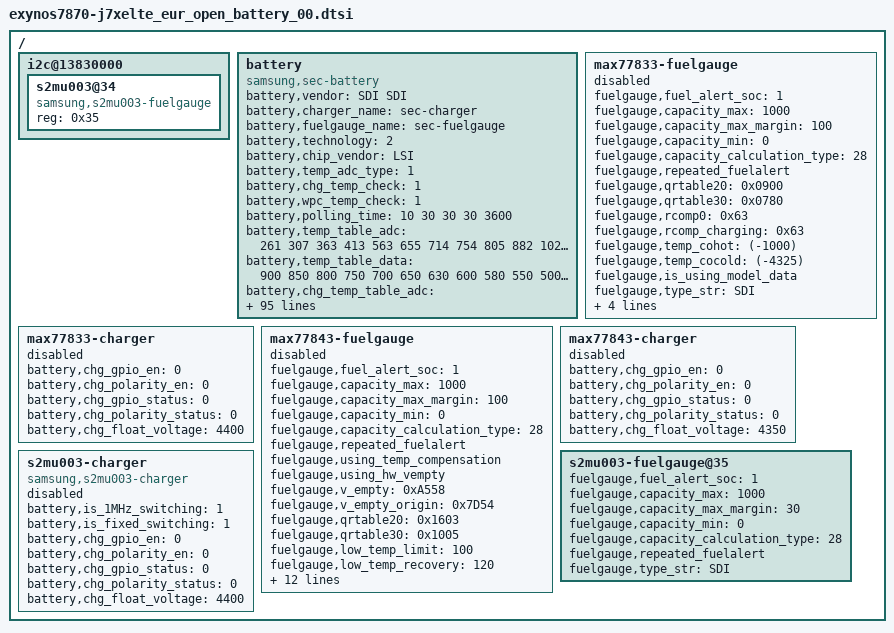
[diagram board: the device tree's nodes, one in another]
/*
 * SAMSUNG UNIVERSAL5433 board device tree source
 *
 * Copyright (c) 2013 Samsung Electronics Co., Ltd.
 *		http://www.samsung.com
 *
 * This program is free software; you can redistribute it and/or modify
 * it under the terms of the GNU General Public License version 2 as
 * published by the Free Software Foundation.
*/

/ {
	i2c@13830000 {
		status = "okay";
		s2mu003@34 {
			compatible = "samsung,s2mu003-fuelgauge";
			reg = <0x35>;
			pinctrl-names = "default";
		};
	};

	battery {
		status = "okay";

		compatible = "samsung,sec-battery";
		battery,vendor = "SDI SDI";
		battery,charger_name = "sec-charger";
		battery,fuelgauge_name = "sec-fuelgauge";
		battery,technology = <2>; /* POWER_SUPPLY_TECHNOLOGY_LION */
		/* .temp_cohot = -1000; */
		/* .temp_cocold = -4325; */

		battery,chip_vendor = "LSI";
		battery,temp_adc_type = <1>; /* SEC_BATTERY_ADC_TYPE_AP */

		battery,chg_temp_check = <1>;
		battery,wpc_temp_check = <1>;

		battery,polling_time = <10 30 30 30 3600>;

		battery,temp_table_adc = <261 307 363 413 563 655 714 754 805 882 1025 1192 1265 1377 1578
					 1798 2032 2268 2493 2720 2959 3155 3266 3340 3495 3627 3727>;
		battery,temp_table_data = <900 850 800 750 700 650 630 600 580 550 500 450 430 400 350
					  300 250 200 150 100 50 0 (-30) (-50) (-100) (-150) (-200)>;

		battery,chg_temp_table_adc = <542 638 665 733 782 855 1000 1168 1237 1341 1530
					     1736 1949 2170 2378 2583 2801 2975 3081 3149 3284 3413 3504>;
		battery,chg_temp_table_data = <700 650 630 600 580 550 500 450 430 400 350
					    300 250 200 150 100 50 0 (-30) (-50) (-100) (-150) (-200)>;

		battery,input_current_limit = <1800 460 460 1800 460 900 1000 460 1000 0 820 820 820 1900 1800 0 0 400 700 1300 300 1000 1500 0 1667 1667 1000 1667 80 1800 1667 1400 1000 1000 820 820>;
		battery,fast_charging_current = <2100 0 0 2100 460 1200 1000 460 1200 0 1200 1200 1200 1600 2100 0 0 400 700 1300 300 1000 1500 0 2550 2550 1000 2550 80 1800 1000 1400 0 1000 1200 1200>;
		battery,full_check_current_1st = <350 0 0 350 350 350 350 350 350 0 350 350 350 350 350 0 0 350 350 350 350 350 350 0 350 350 350 350 0 350 350 350 0 350 350 350>;
		battery,full_check_current_2nd = <175 0 0 175 175 175 175 175 175 0 175 175 175 175 175 0 0 175 175 175 175 175 175 0 175 175 175 175 0 175 175 175 0 175 175 175>;

		battery,wireless_cc_cv = <86>;
		battery,inbat_voltage = <1>;

		battery,inbat_voltage_table_adc = <3120 3101 3061 3038 3001 2956 2920 2887 2856 2814
						2793 2754 2720 2677 2641 2613 2572 2531 2502 2467 2436>;
		battery,inbat_voltage_table_data = <438 435 430 425 420 415 410 405 400 395
						390 385 380 375 370 365 360 355 350 345 340>;

		battery,adc_check_count = <5>;

		battery,cable_check_type = <4>; /* SEC_BATTERY_CABLE_CHECK_PSY */
		battery,cable_source_type = <1>; /* SEC_BATTERY_CABLE_SOURCE_EXTERNAL */
		battery,polling_type = <1>; /* SEC_BATTERY_MONITOR_ALARM */
		battery,monitor_initial_count = <0>;

		battery,battery_check_type = <0>;
		battery,check_count = <0>;
		battery,check_adc_max = <1440>;
		battery,check_adc_min = <0>;

		battery,ovp_uvlo_check_type = <3>; /* SEC_BATTERY_OVP_UVLO_CHGPOLLING */

		battery,thermal_source = <2>; /* SEC_BATTERY_THERMAL_SOURCE_ADC */

		battery,temp_check_type = <2>; /* _BATTERY_TEMP_CHECK_TEMP */
		battery,temp_check_count = <1>;
		battery,temp_highlimit_threshold_normal = <800>;
		battery,temp_highlimit_recovery_normal = <750>;
		battery,temp_high_threshold_normal = <500>;
		battery,temp_high_recovery_normal = <450>;
		battery,temp_low_threshold_normal = <0>;
		battery,temp_low_recovery_normal = <50>;
		battery,temp_highlimit_threshold_lpm = <800>;
		battery,temp_highlimit_recovery_lpm = <750>;
		battery,temp_high_threshold_lpm = <500>;
		battery,temp_high_recovery_lpm = <450>;
		battery,temp_low_threshold_lpm = <0>;
		battery,temp_low_recovery_lpm = <50>;
		
		battery,full_check_type = <7>; /* SEC_BATTERY_FULLCHARGED_CHGPSY */
		battery,full_check_type_2nd = <7>; /* SEC_BATTERY_FULLCHARGED_CHGPSY */
		battery,full_check_count = <1>;
		battery,chg_gpio_full_check = <0>;
		battery,chg_polarity_full_check = <1>;

		battery,chg_high_temp_1st = <530>;
		battery,chg_high_temp_2nd = <530>;
		battery,chg_high_temp_recovery = <525>;
		battery,chg_charging_limit_current = <1300>;
		battery,chg_charging_limit_current_2nd = <1300>;
		battery,chg_skip_check_capacity = <10>;
		battery,chg_skip_check_time = <600>;

		battery,wpc_high_temp = <420>;
		battery,wpc_high_temp_recovery = <410>;
		battery,wpc_charging_limit_current = <450>;

		/* SEC_BATTERY_FULL_CONDITION_SOC |
		   SEC_BATTERY_FULL_CONDITION_NOTIMEFULL |
		   SEC_BATTERY_FULL_CONDITION_VCELL */
		battery,full_condition_type = <13>;
		battery,full_condition_soc = <93>;
		battery,full_condition_vcell = <4275>;

		battery,recharge_check_count = <2>;
		battery,recharge_condition_type = <4>; /* SEC_BATTERY_RECHARGE_CONDITION_VCELL */
		battery,recharge_condition_soc = <98>;
		battery,recharge_condition_vcell = <4250>;

		battery,charging_total_time = <21600>;
		battery,recharging_total_time = <5400>;
		battery,charging_reset_time = <0>;
		
		battery,expired_time = <15000>;
		battery,recharging_expired_time = <5400>;
		battery,standard_curr = <1800>;

		battery,chg_float_voltage = <4350>;

		battery,self_discharging_en;
		battery,force_discharging_limit = <650>;
		battery,force_discharging_recov = <550>;
		battery,self_discharging_voltage_limit = <4250>;
		battery,discharging_adc_max = <2600>;
		battery,discharging_adc_min = <1700>;
		battery,discharging_ntc_limit = <2750>;

		battery,swelling_high_temp_block = <410>;
		battery,swelling_high_temp_recov = <390>;
		
		battery,swelling_low_temp_2step_mode = <1>;
		battery,swelling_low_temp_block_1st = <150>;
		battery,swelling_low_temp_recov_1st = <200>;
		battery,swelling_low_temp_block_2nd = <100>;
		battery,swelling_low_temp_recov_2nd = <150>;
		
		battery,swelling_low_temp_current = <990>;	/* 0.3C */
		battery,swelling_low_temp_topoff = <140>;	/* 0.05C */
		battery,swelling_high_temp_current = <1485>;	/* 0.45C */
		battery,swelling_high_temp_topoff = <140>;	/* 0.05C */
		
		battery,swelling_drop_float_voltage = <4200>;
		battery,swelling_high_rechg_voltage = <4150>;
		battery,swelling_low_rechg_voltage = <4050>;

		io-channels = <&exynos_adc 1>, <&exynos_adc 3>, <&exynos_adc 6>, <&exynos_adc 5>, <&exynos_adc 7>;
		io-channel-names = "adc-temp", "adc-chg-temp", "adc-in-bat", "adc-dischg", "adc-dischg-ntc";
		#io-channel-cells = <5>;
		io-channel-ranges;
	};

	max77833-fuelgauge {
		status = "disable";
		fuelgauge,fuel_alert_soc = <1>;
		fuelgauge,capacity_max = <1000>;
		fuelgauge,capacity_max_margin = <100>;
		fuelgauge,capacity_min = <0>;
		fuelgauge,capacity_calculation_type = <28>;
		fuelgauge,repeated_fuelalert;
		fuelgauge,qrtable20 = <0x0900>;
		fuelgauge,qrtable30 = <0x0780>;
		fuelgauge,rcomp0 = <0x63>;
		fuelgauge,rcomp_charging = <0x63>;
		fuelgauge,temp_cohot = <(-1000)>;
		fuelgauge,temp_cocold = <(-4325)>;
		fuelgauge,is_using_model_data;
		fuelgauge,type_str = "SDI";
		fuelgauge,capacity = <0x19C8>;
		fuelgauge,low_battery_comp_voltage = <3600>;
		fuelgauge,low_battery_table = <(-5000) 0 0 (-1250) 0 3320 (-750) 97 3451 (-100) 96 3461 0 0 3456>;

	};
	max77833-charger {
	        status = "disable";
		battery,chg_gpio_en = <0>;
		battery,chg_polarity_en = <0>;
		battery,chg_gpio_status = <0>;
		battery,chg_polarity_status = <0>;
		battery,chg_float_voltage = <4400>;
	};

	max77843-fuelgauge {
		status = "disable";
		fuelgauge,fuel_alert_soc = <1>;
		fuelgauge,capacity_max = <1000>;
		fuelgauge,capacity_max_margin = <100>;
		fuelgauge,capacity_min = <0>;
		fuelgauge,capacity_calculation_type = <28>;
		fuelgauge,repeated_fuelalert;
		fuelgauge,using_temp_compensation;
		fuelgauge,using_hw_vempty;
		fuelgauge,v_empty = <0xA558>;
		fuelgauge,v_empty_origin = <0x7D54>;
		fuelgauge,qrtable20 = <0x1603>;
		fuelgauge,qrtable30 = <0x1005>;
		fuelgauge,low_temp_limit = <100>;
		fuelgauge,low_temp_recovery = <120>;
		fuelgauge,temp_cohot = <0x1B45>;
		fuelgauge,temp_cocold = <0x194D>;
		fuelgauge,rcomp0 = <0x35>;
		fuelgauge,rcomp_charging = <0x35>;
		fuelgauge,is_using_model_data;
		fuelgauge,type_str = "SDI";
		fuelgauge,capacity = <0x1438>;
		fuelgauge,low_battery_comp_voltage = <3600>;
		fuelgauge,low_battery_table = <(-5000) 0 0 (-1250) 0 3320 (-750) 97 3451 (-100) 96 3461 0 0 3456>;
		fuelgauge,cv_data = <2565  680    2580
			2483  688    2549
			2405  696    2519
			2333  704    2489
			2263  711    2458
			2196  718    2428
			2137  725    2398
			2077  732    2367
			2016  738    2337
			1964  745    2306
			1894  751    2276
			1835  757    2246
			1783  763    2215
			1727  769    2185
			1674  774    2155
			1621  780    2124
			1571  785    2094
			1525  790    2064
			1480  795    2033
			1437  800    2003
			1391  804    1973
			1353  809    1942
			1311  814    1912
			1272  818    1882
			1235  822    1851
			1198  826    1821
			1161  830    1791
			1124  834    1760
			1092  838    1730
			1059  841    1700
			1027  845    1669
			996   848    1639
			969   852    1608
			940   855    1578
			909   858    1548
			885   861    1517
			863   864    1487
			840   867    1457
			817   870    1426
			794   872    1396
			771   875    1366
			749   878    1335
			725   880    1305
			707   883    1275
			696   885    1244
			674   887    1214
			658   890    1184
			640   892    1153
			618   894    1123
			608   896    1093
			604   898    1062
			584   900    1032
			567   903    1002
			553   909    971
			539   913    941
			524   918    910
			515   921    880
			507   924    850
			494   929    820
			476   934    789
			469   937    759
			459   939    729
			449   943    698
			438   946    668
			431   949    638
			419   952    607
			408   957    577
			402   958    546
			389   962    516
			385   964    486
			377   966    455
			371   968    425
			359   972    395
			353   975    364
			347   976    334
			337   979    304
			331   981    273
			327   983    243
			323   985    213
			319   986    182
			306   989    152
			303   992    122
			298   993    91
			293   996    61
			290   997    31
			0     1000   0 >;
	};
	max77843-charger {
	        status = "disable";
		battery,chg_gpio_en = <0>;
		battery,chg_polarity_en = <0>;
		battery,chg_gpio_status = <0>;
		battery,chg_polarity_status = <0>;
		battery,chg_float_voltage = <4350>;
	};

	s2mu003-fuelgauge@35 {
		fuelgauge,fuel_alert_soc = <1>;
		fuelgauge,capacity_max = <1000>;
		fuelgauge,capacity_max_margin = <30>;
		fuelgauge,capacity_min = <0>;
		fuelgauge,capacity_calculation_type = <28>;
		fuelgauge,repeated_fuelalert;
		fuelgauge,type_str = "SDI";
	};

	s2mu003-charger {
		status = "disable";
		compatible = "samsung,s2mu003-charger";
		battery,is_1MHz_switching = <1>;
		battery,is_fixed_switching = <1>;
		battery,chg_gpio_en = <0>;
		battery,chg_polarity_en = <0>;
		battery,chg_gpio_status = <0>;
		battery,chg_polarity_status = <0>;
		battery,chg_float_voltage = <4400>;
	};

};
